# MU3E_FULL8LANE_TYPE0_SYSTEM_SC_HUB register map
Vendor: Mu3e; Series: MU3E_FULL8LANE_TYPE0; File version: 2026.05.06
Registers are 32-bit, read-write, reset 0x0 unless marked. A register's access mark holds for its fields unless they carry their own. Offsets are from the block's base; [hi:lo] are bit positions; {n}, {i} and the like mark numbered series.

## SCRATCH_PAD_RAM_S1 — Direct control-path slave reached from sc_hub_cmd_pipe.m0. Qsys slave scratch_pad_ram.s1 is SC-hub-relative at 0x00000000 with compiled aperture size 0x00000400. Compiled Qsys module scratch_pad_ram kind=altera_avalon_onchip_memory2 version=18.1 from full8lane_control_path_subsystem.qsys. Source SVD toolkits/infra/cmsis_svd/generic/scratch_pad_ram.svd version 1.0.0. Relative 256-word read/write scratchpad aperture.
Base 0x00000000
{0x0+4i} WORD{i:03} (i=0..255) — Scratchpad RAM word {i}.
  [31:0] value — Raw scratchpad word {i}.

## ONEWIRE_MASTER_CONTROLLER_0_CSR — Direct control-path slave reached from sc_hub_cmd_pipe.m0. Qsys slave onewire_master_controller_0.csr is SC-hub-relative at 0x00011000 with compiled aperture size 0x0000002C. Compiled Qsys module onewire_master_controller_0 kind=onewire_master_controller version=26.2.1.428 from full8lane_control_path_subsystem.qsys. Version/identity parameters: VERSION_MAJOR=26, VERSION_MINOR=2, VERSION_PATCH=1, BUILD=428, VERSION_DATE=20260428, VERSION_GIT=0, IP_UID=1331121475, INSTANCE_ID=0. Source SVD onewire_temp_sense/script/onewire_master_controller.svd version 26.2.1. Relative 11-word 1-Wire controller CSR aperture with common Mu3e UID/META header.
Base 0x00011000
0x00 UID ro reset 0x4F574D43 — Common Mu3e software-visible IP identifier. Default is ASCII OWMC.
  [31:0] ip_uid — HDL parameter IP_UID.
0x04 META — Common read-multiplexed metadata word. Writes select the readback page: 0 VERSION, 1 VERSION_DATE, 2 VERSION_GIT, 3 INSTANCE_ID.
  [1:0] selector — Write page selector. 0 VERSION, 1 VERSION_DATE, 2 VERSION_GIT, 3 INSTANCE_ID.
  [31:0] payload ro — Readback payload for the selected metadata page. VERSION page encoding is MAJOR bits 31..24, MINOR bits 23..16, PATCH bits 15..12, BUILD bits 11..0.
0x08 SCRATCH — Software scratch/readback word for CSR liveness tests.
  [31:0] value — Read/write scratchpad value, reset to zero.
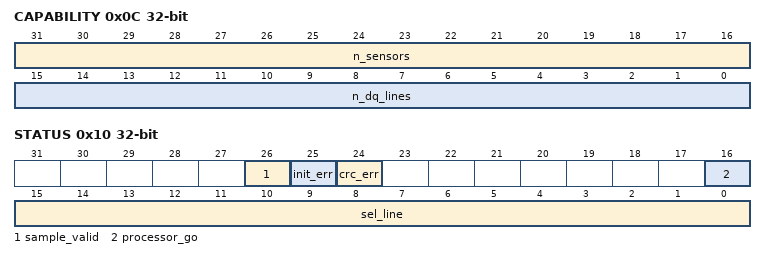
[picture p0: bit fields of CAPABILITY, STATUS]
0x0C CAPABILITY ro — 1-Wire controller capability register.
  [31:16] n_sensors — Reserved for future sensor-count reporting; currently reads zero.
  [15:0] n_dq_lines — Number of 1-Wire DQ lines synthesized into this instance.
0x10 STATUS — Line select and per-line control/status register. Reads return the selected line and its sticky error summary. Writes update sel_line and processor_go for the addressed line.
  [26] sample_valid ro — Full DS18B20 scratchpad has been captured for the selected line after reset or the latest read transaction started.
  [25] init_err ro — Initialization error sticky flag for the selected line.
  [24] crc_err ro — CRC error sticky flag for the selected line.
  [16] processor_go — Enable or disable the background measurement processor for the selected line.
  [15:0] sel_line — Selected DQ line index for readback and processor_go writes.
{0x14+4i} SENSOR{i}_TEMP_F32 ro (i=0..5) — IEEE-754 float32 temperature reading for sensor {i}.
  [31:0] value — Raw float32 temperature sample for sensor {i}.

## CHARGE_INJECTION_PULSER_0_CSR_AVMM — Direct control-path slave reached from sc_hub_cmd_pipe.m0. Qsys slave charge_injection_pulser_0.csr_avmm is SC-hub-relative at 0x00013000 with compiled aperture size 0x00000004. Compiled Qsys module charge_injection_pulser_0 kind=charge_injection_pulser version=4.0.5 from full8lane_control_path_subsystem.qsys. Source SVD charge_injection/legacy/charge_injection_pulser.svd version 4.0.5. Single-word write-only CSR aperture for charge-injection pulse generation.
Base 0x00013000
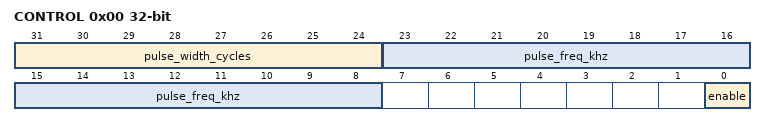
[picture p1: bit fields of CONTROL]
0x00 CONTROL wo — Write-only charge-injection pulser control word. Bit 0 enables the generator. Bits [23:8] program the pulse repetition frequency in kHz. Bits [31:24] program the pulse width in clock cycles. Reads are not implemented by the RTL and should not be issued.
  [31:24] pulse_width_cycles — Pulse width in clock cycles. Zero selects the compile-time default.
  [23:8] pulse_freq_khz — Pulse repetition frequency in kHz. Zero selects the compile-time default.
  [0] enable — 1 enables periodic pulse generation; 0 disables the output.
